# M55M1 register map
File version: 1.0
Registers are 32-bit, read-write, reset 0x0 unless marked. A register's access mark holds for its fields unless they carry their own. Offsets are from the block's base; [hi:lo] are bit positions; {n}, {i} and the like mark numbered series; 'fields as' and 'values as' point back to an identical list.

## OTFC0 — OTFC Register Map
Base 0x40040000
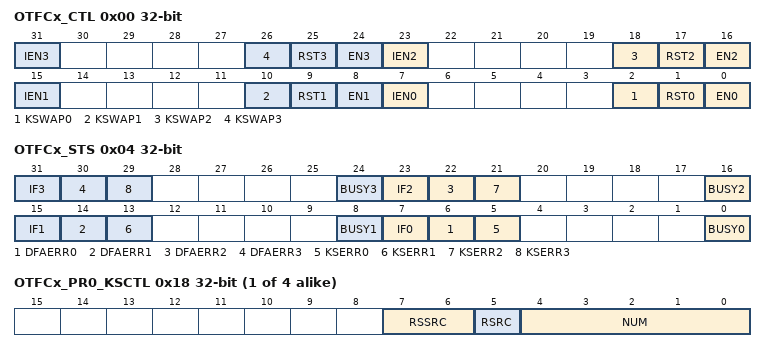
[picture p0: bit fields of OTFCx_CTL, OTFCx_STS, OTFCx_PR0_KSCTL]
0x00 OTFCx_CTL — OTFC Control Register
  [8n+7] IEN{n} (n=0..3) — Protection Region {n} Interrupt Enable Bit
    0=Protection Region {n} interrupt Disabled; 1=Protection Region {n} interrupt Enabled
  [8n+2] KSWAP{n} (n=0..3) — Protection Region {n} Key Swap
    0=Keep the original order in OTFCx_PR{n}_KEYy; 1=The order that CPU feeds key to the accelerator will be changed from {byte3, byte2, byte1, byte0} to {byte0, byte1, byte2, byte3}
  [8n+1] RST{n} (n=0..3) — Protection Region {n} Reset. Note: This bit is always 0 when it is read back.
    0=No effect; 1=Clear the setting of OTFC protection region {n}
  [8n] EN{n} (n=0..3) — Protection Region {n} Enable
    0=No effect; 1=OTFC protection region {n} Enabled
0x04 OTFCx_STS — OTFC Status Flag Register
  [8n+7] IF{n} (n=0..3) — OTFC Protrction Region {n} Interrupt Flag. Note: This bit is cleared by writing 1 and it has no effect by writing 0.
    0=No OTFC Protrction Region {n} interrupt; 1=OTFC Protrction Region {n} interrupt
  [8n+6] DFAERR{n} ro (n=0..3) — OTFC Protrction Region {n} Differential Fault Attack Error Flag (Read Only)
    0=No error; 1=Differential Fault Attack happened in protrction region {n}. The results from AES engine are incorrect
  [8n+5] KSERR{n} ro (n=0..3) — OTFC Protrction Region {n} Access Key Store Error Flag (Read Only)
    0=No error; 1=Key Store access error will stop OTFC engine in Protrction Region {n}
  [8n] BUSY{n} ro (n=0..3) — OTFC Protrction Region {n} Busy (Read Only)
    0=The OTFC Protrction Region {n} is idle; 1=The OTFC Protrction Region {n} is under processing
{0x10+0x40*i} OTFCx_PR{i}_SADDR (i=0..3) — OTFC Protection Region {i} Start Address Register
  [31:0] SADDR — Protection Region {i} Start Address Register. The start address indicates the start address of protection region {i} in the external memory space for OTFC. The start address should be located at 128-bit boundary. In other words, bit 3, 2, 1 and 0 of SADDR are ignored. SADDR can be read and written.
{0x14+0x40*i} OTFCx_PR{i}_EADDR (i=0..3) — OTFC Protection Region {i} End Address Register
  [31:0] EADDR — OTFC Protection Region {i} End Address. The end address indicates the end address of protection region {i} in the external memory space for OTFC. The end address should be located at 128-bit boundary. In other words, bit 3, 2, 1 and 0 of EADDR are ignored. EADDR can be read and written
{0x18+0x40*i} OTFCx_PR{i}_KSCTL wo (i=0..3) — OTFC Protection Region {i} Key Control Register
  [7:6] RSSRC — Read Key Store Source. RSSRC takes effect only when RSRC is 1 (the key is from Key Store).
    0=Key is read from the SRAM of Key Store; 2=Key is read from the OTP of Key Store
  [5] RSRC — Read Key Source
    0=Key is read from registers OTFC_PR{i}_KEYx; 1=Key is read from Key Store
  [4:0] NUM — Read Key Number. The key number is sent to Key Store
{0x20+4i} OTFCx_PR0_KEY{i} wo (i=0..3) — OTFC Protection Region 0 KEY Word {i} Register
  [31:0] KEY — OTFC_PR0_KEYy. The KEY keeps the security key for AES operation in protection region 0. The security key for AES accelerator is 128 bits and four 32-bit registers are to store each security key. {OTFC_PR0_KEY3, OTFC_PR0_KEY2, OTFC_PR0_KEY1, OTFC_PR0_KEY0} stores the 128-bit security key for AES operation.
{0x40+0x40*i} OTFCx_PR{i}_SCRAMBLE wo (i=0..3) — OTFC Protection Region {i} Scramble key Register
  [31:0] SCRAMBLE — Protection Region {i} Scramble key Register. The scramble key for address cipher function in protection region {i}.
{0x44+0x40*i} OTFCx_PR{i}_NONCE0 wo (i=0..3) — OTFC Protection Region {i} Nonce Word 0 Register
  [31:0] NONCE — Protection Region {i} Nonce Word y Register. Three nonces (OTFC_PR{i}_NONCE0, OTFC_PR{i}_NONCE1, and OTFC_PR{i}_NONCE2) are for the address cipher function in OTFC.
{0x48+0x40*i} OTFCx_PR{i}_NONCE1 wo (i=0..3) — OTFC Protection Region {i} Nonce Word 1 Register
  fields as OTFCx_PR0_NONCE0
{0x4C+0x40*i} OTFCx_PR{i}_NONCE2 wo (i=0..3) — OTFC Protection Region {i} Nonce Word 2 Register
  fields as OTFCx_PR0_NONCE0
{0x60+4i} OTFCx_PR1_KEY{i} wo (i=0..3) — OTFC Protection Region 1 KEY Word {i} Register
  [31:0] KEY — OTFC_PR1_KEYy. The KEY keeps the security key for AES operation in protection region 1. The security key for AES accelerator is 128 bits and four 32-bit registers are to store each security key. {OTFC_PR1_KEY3, OTFC_PR1_KEY2, OTFC_PR1_KEY1, OTFC_PR1_KEY0} stores the 128-bit security key for AES operation.
{0xA0+4i} OTFCx_PR2_KEY{i} wo (i=0..3) — OTFC Protection Region 2 KEY Word {i} Register
  [31:0] KEY — OTFC_PR2_KEYy. The KEY keeps the security key for AES operation in protection region 2. The security key for AES accelerator is 128 bits and four 32-bit registers are to store each security key. {OTFC_PR2_KEY3, OTFC_PR2_KEY2, OTFC_PR2_KEY1, OTFC_PR2_KEY0} stores the 128-bit security key for AES operation.
{0xE0+4i} OTFCx_PR3_KEY{i} wo (i=0..3) — OTFC Protection Region 3 KEY Word {i} Register
  [31:0] KEY — OTFC_PR3_KEYy. The KEY keeps the security key for AES operation in protection region 3. The security key for AES accelerator is 128 bits and four 32-bit registers are to store each security key. {OTFC_PR3_KEY3, OTFC_PR3_KEY2, OTFC_PR3_KEY1, OTFC_PR1_KEY0} stores the 128-bit security key for AES operation.
